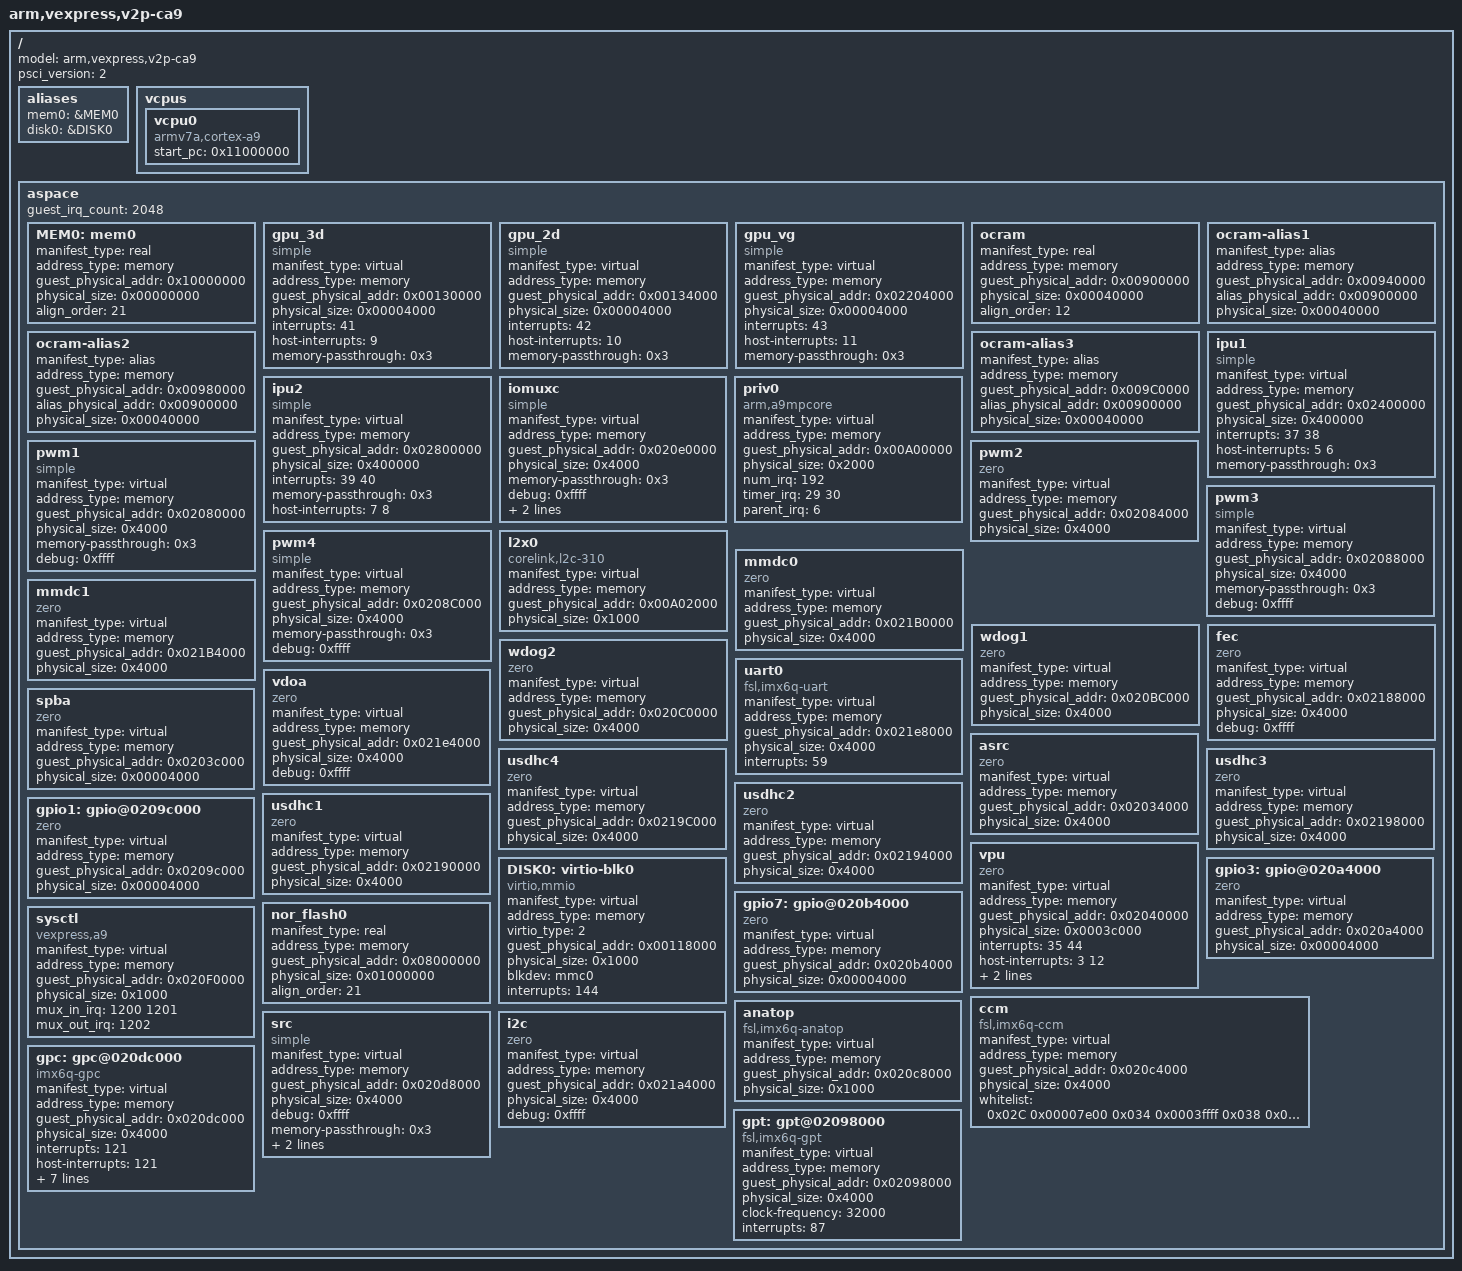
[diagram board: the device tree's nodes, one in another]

/dts-v1/;

/ {
	model = "arm,vexpress,v2p-ca9";
	device_type = "guest";
	psci_version = <2>;

	aliases {
		mem0 = &MEM0;
		//net0 = &NET0;
		disk0 = &DISK0;
	};

	vcpus {
		vcpu0 {
			device_type = "vcpu";
			compatible = "armv7a,cortex-a9";
			start_pc = <0x11000000>;
		};

		/* vcpu1 { */
		/* 	device_type = "vcpu"; */
		/* 	compatible = "armv7a,cortex-a9"; */
		/* 	start_pc = <0xC1000000>; */
		/* }; */
	};

	aspace {
		guest_irq_count = <2048>;

		MEM0: mem0 {
			manifest_type = "real";
			address_type = "memory";
			guest_physical_addr = <0x10000000>;
			physical_size = <0x00000000>; /* Override this before guest creation */
			align_order = <21>; /* Align alloced memory to 2MB */
			device_type = "alloced_ram";
		};

		gpu_3d {
			manifest_type = "virtual";
			address_type = "memory";
			guest_physical_addr = <0x00130000>;
			physical_size = <0x00004000>;
			interrupts = <41>;
			host-interrupts = <9>;
			memory-passthrough = <0x3>;
			//debug = <0xffffffff>;
			device_type = "pt";
			compatible = "simple";
		};

		gpu_2d {
			manifest_type = "virtual";
			address_type = "memory";
			guest_physical_addr = <0x00134000>;
			physical_size = <0x00004000>;
			interrupts = <42>;
			host-interrupts = <10>;
			memory-passthrough = <0x3>;
			device_type = "pt";
			compatible = "simple";
			//debug = <0xffffffff>;
		};

		gpu_vg {
			manifest_type = "virtual";
			address_type = "memory";
			guest_physical_addr = <0x02204000>;
			physical_size = <0x00004000>;
			interrupts = <43>;
			host-interrupts = <11>;
			memory-passthrough = <0x3>;
			//debug = <0xffffffff>;
			device_type = "pt";
			compatible = "simple";
		};

		ocram {
			manifest_type = "real";
			address_type = "memory";
			guest_physical_addr = <0x00900000>;
			physical_size = <0x00040000>;
			align_order = <12>; /* Align alloced memory to 4K */
			device_type = "alloced_ram";
		};

		ocram-alias1 {
			manifest_type = "alias";
			address_type = "memory";
			guest_physical_addr = <0x00940000>;
			alias_physical_addr = <0x00900000>;
			physical_size = <0x00040000>;
			device_type = "ram";
		};

		ocram-alias2 {
			manifest_type = "alias";
			address_type = "memory";
			guest_physical_addr = <0x00980000>;
			alias_physical_addr = <0x00900000>;
			physical_size = <0x00040000>;
			device_type = "ram";
		};

		ocram-alias3 {
			manifest_type = "alias";
			address_type = "memory";
			guest_physical_addr = <0x009C0000>;
			alias_physical_addr = <0x00900000>;
			physical_size = <0x00040000>;
			device_type = "ram";
		};

		ipu1 {
			manifest_type = "virtual";
			address_type = "memory";
			guest_physical_addr = <0x02400000>;
			physical_size = <0x400000>;
			interrupts = <37 38>;
			host-interrupts = <5 6>;
			memory-passthrough = <0x3>;
			device_type = "pt";
			compatible = "simple";
			///debug = <0xffff>;
		};

		ipu2 {
			manifest_type = "virtual";
			address_type = "memory";
			guest_physical_addr = <0x02800000>;
			physical_size = <0x400000>;
			interrupts = <39 40>;
			memory-passthrough = <0x3>;
			host-interrupts = <7 8>;
			device_type = "pt";
			compatible = "simple";
			///debug = <0xffff>;
		};

		iomuxc {
			manifest_type = "virtual";
			address_type = "memory";
			guest_physical_addr = <0x020e0000>;
			physical_size = <0x4000>;
			device_type = "pt";
			compatible = "simple";
			memory-passthrough = <0x3>;
			//device_type = "misc";
			//compatible = "fsl,imx6q-iomuxc";
			debug = <0xffff>;
			whitelist = <
				0x004 0x00021000
				0x008 0xffffffff /* LDB */
				0x00C 0x600007ff
				0x010 0x000000ff
				0x018 0xffffffff
				0x01C 0xffffffff

				0x15C 0xffffffff
				0x160 0xffffffff
				0x164 0xffffffff
				0x168 0xffffffff
				0x170 0xffffffff
				0x174 0xffffffff
				0x178 0xffffffff
				0x17C 0xffffffff
				0x180 0xffffffff
				0x184 0xffffffff
				0x188 0xffffffff
				0x18C 0xffffffff
				0x190 0xffffffff
				0x194 0xffffffff
				0x198 0xffffffff
				0x19C 0xffffffff
				0x1A0 0xffffffff
				0x1A4 0xffffffff
				0x1A8 0xffffffff
				0x1AC 0xffffffff
				0x1B0 0xffffffff
				0x1B4 0xffffffff
				0x1B8 0xffffffff
				0x1BC 0xffffffff
				0x1C0 0xffffffff
				0x1C4 0xffffffff
				0x1C8 0xffffffff
				0x1CC 0xffffffff

				0x470 0xffffffff
				0x474 0xffffffff
				0x478 0xffffffff
				0x47C 0xffffffff
				0x484 0xffffffff
				0x488 0xffffffff
				0x48C 0xffffffff
				0x490 0xffffffff
				0x494 0xffffffff
				0x498 0xffffffff
				0x49C 0xffffffff
				0x4A0 0xffffffff
				0x4A4 0xffffffff
				0x4A8 0xffffffff
				0x4AC 0xffffffff
				0x4B0 0xffffffff
				0x4B4 0xffffffff
				0x4B8 0xffffffff
				0x4BC 0xffffffff
				0x4C0 0xffffffff
				0x4C4 0xffffffff
				0x4C8 0xffffffff
				0x4CC 0xffffffff
				0x4D0 0xffffffff
				0x4D4 0xffffffff
				0x4D8 0xffffffff
				0x4DC 0xffffffff
				0x4E0 0xffffffff
			>;
		//	device_type = "pt";
		//	memory-passthrough = <0x3>;
		//	compatible = "simple";
		//	host-interrupts = <32>;
		//	interrupts = <32>;
		};

		//dma_apbh {
		//	manifest_type = "virtual";
		//	address_type = "memory";
		//	guest_physical_addr = <0x00110000>;
		//	physical_size = <0x2000>;
		//	device_type = "misc";
		//	compatible = "fsl,imx6q-dma-apbh";
		//	debug = <0xffff>;
		//};

		priv0 {
			manifest_type = "virtual";
			address_type = "memory";
			guest_physical_addr = <0x00A00000>;
			physical_size = <0x2000>;
			device_type = "misc";
			compatible = "arm,a9mpcore";
			num_irq = <192>;
			timer_irq = <29 30>;
			parent_irq = <6>;
		//	debug = <0xffff>;
		};

		pwm1 {
			manifest_type = "virtual";
			address_type = "memory";
			guest_physical_addr = <0x02080000>;
			physical_size = <0x4000>;

			//device_type = "misc";
			//compatible = "zero";
			device_type = "pt";
			compatible = "simple";
			memory-passthrough = <0x3>;
			debug = <0xffff>;
		};

		pwm2 {
			manifest_type = "virtual";
			address_type = "memory";
			guest_physical_addr = <0x02084000>;
			physical_size = <0x4000>;
			device_type = "misc";
			compatible = "zero";
		};

		pwm3 {
			manifest_type = "virtual";
			address_type = "memory";
			guest_physical_addr = <0x02088000>;
			physical_size = <0x4000>;
			//device_type = "misc";
			//compatible = "zero";

			device_type = "pt";
			compatible = "simple";
			memory-passthrough = <0x3>;
			debug = <0xffff>;
		};

		pwm4 {
			manifest_type = "virtual";
			address_type = "memory";
			guest_physical_addr = <0x0208C000>;
			physical_size = <0x4000>;

			device_type = "pt";
			compatible = "simple";
			memory-passthrough = <0x3>;
			debug = <0xffff>;
			//device_type = "misc";
			//compatible = "zero";
		};

		l2x0 {
			manifest_type = "virtual";
			address_type = "memory";
			guest_physical_addr = <0x00A02000>;
			physical_size = <0x1000>;
			device_type = "cache";
			compatible = "corelink,l2c-310";
		};

                mmdc0 {
			manifest_type = "virtual";
			address_type = "memory";
			guest_physical_addr = <0x021B0000>;
			physical_size = <0x4000>;
			device_type = "misc";
			compatible = "zero";
                };

                mmdc1 {
			manifest_type = "virtual";
			address_type = "memory";
			guest_physical_addr = <0x021B4000>;
			physical_size = <0x4000>;
			device_type = "misc";
			compatible = "zero";
                };

		wdog1 {
			manifest_type = "virtual";
			address_type = "memory";
			guest_physical_addr = <0x020BC000>;
			physical_size = <0x4000>;
			device_type = "misc";
			compatible = "zero";
		};

                fec {
			manifest_type = "virtual";
			address_type = "memory";
			guest_physical_addr = <0x02188000>;
			physical_size = <0x4000>;
			device_type = "misc";
			debug = <0xffff>;
			compatible = "zero";
                };

		wdog2 {
			manifest_type = "virtual";
			address_type = "memory";
			guest_physical_addr = <0x020C0000>;
			physical_size = <0x4000>;
			device_type = "misc";
			compatible = "zero";
		};

		uart0 {
			manifest_type = "virtual";
			address_type = "memory";
			guest_physical_addr = <0x021e8000>;
			physical_size = <0x4000>;
			device_type = "serial";
			compatible = "fsl,imx6q-uart", "fsl,imx21-uart";
			interrupts = <59>;
		};

		vdoa {
			manifest_type = "virtual";
			address_type = "memory";
			guest_physical_addr = <0x021e4000>;
			physical_size = <0x4000>;
			device_type = "misc";
			compatible = "zero";
			debug = <0xffff>;
		};

		spba {
			manifest_type = "virtual";
			address_type = "memory";
			guest_physical_addr = <0x0203c000>;
			physical_size = <0x00004000>;
			device_type = "misc";
			compatible = "zero";
		};

		//sdma {
		//	manifest_type = "virtual";
		//	address_type = "memory";
		//	guest_physical_addr = <0x020ec000>;
		//	physical_size = <0x4000>;
		//	device_type = "misc";
		//	compatible = "zero";
                //};

                asrc {
			manifest_type = "virtual";
			address_type = "memory";
			guest_physical_addr = <0x02034000>;
			physical_size = <0x4000>;
			device_type = "misc";
			compatible = "zero";
		};

                usdhc4 {
			manifest_type = "virtual";
			address_type = "memory";
			guest_physical_addr = <0x0219C000>;
			physical_size = <0x4000>;
			device_type = "misc";
			compatible = "zero";
                };

                usdhc3 {
			manifest_type = "virtual";
			address_type = "memory";
			guest_physical_addr = <0x02198000>;
			physical_size = <0x4000>;
			device_type = "misc";
			compatible = "zero";
		};

                usdhc2 {
			manifest_type = "virtual";
			address_type = "memory";
			guest_physical_addr = <0x02194000>;
			physical_size = <0x4000>;
			device_type = "misc";
			compatible = "zero";
                };

                usdhc1 {
			manifest_type = "virtual";
			address_type = "memory";
			guest_physical_addr = <0x02190000>;
			physical_size = <0x4000>;
			device_type = "misc";
			compatible = "zero";
                };

		vpu {
			manifest_type = "virtual";
			address_type = "memory";
			guest_physical_addr = <0x02040000>;
			physical_size = <0x0003c000>;
			interrupts = <35 44>;
			host-interrupts = <3 12>;
			memory-passthrough = <0x3>;
			device_type = "misc";
			compatible = "zero";
			debug = <0xffff>;
	//		device_type = "pt";
	//		compatible = "simple";
		};

		DISK0: virtio-blk0 {
			manifest_type = "virtual";
			address_type = "memory";
			device_type = "virtio";
			compatible = "virtio,mmio";
			virtio_type = <2>; /* virtio_blk */
			guest_physical_addr = <0x00118000>; /* In a "reserved" region */
			physical_size = <0x1000>;
			blkdev = "mmc0"; // XXX: this is just the second partition on the sd card
			interrupts = <144>;
		};

		gpio1: gpio@0209c000 {
			manifest_type = "virtual";
			address_type = "memory";
			guest_physical_addr = <0x0209c000>;
			physical_size = <0x00004000>;
			device_type = "misc";
			compatible = "zero";
		};

		gpio3: gpio@020a4000 {
			manifest_type = "virtual";
			address_type = "memory";
			guest_physical_addr = <0x020a4000>;
			physical_size = <0x00004000>;
			device_type = "misc";
			compatible = "zero";
		};

		gpio7: gpio@020b4000 {
			manifest_type = "virtual";
			address_type = "memory";
			guest_physical_addr = <0x020b4000>;
			physical_size = <0x00004000>;
			device_type = "misc";
			compatible = "zero";
		};

		nor_flash0 {
			manifest_type = "real";
			address_type = "memory";
			guest_physical_addr = <0x08000000>;
			physical_size = <0x01000000>;
			device_type = "alloced_rom";
			align_order = <21>; /* Align alloced memory to 2MB */
		};

		/* Use a reserved i.MX6 area to emulate VExpress-A9 sysctl */
		sysctl {
			manifest_type = "virtual";
			address_type = "memory";
			guest_physical_addr = <0x020F0000>;
			physical_size = <0x1000>;
			device_type = "sys";
			compatible = "vexpress,a9";
			mux_in_irq = <1200 1201>;
			mux_out_irq = <1202>;
		};

		ccm {
			manifest_type = "virtual";
			address_type = "memory";
			guest_physical_addr = <0x020c4000>;
			physical_size = <0x4000>;
			device_type = "misc";
			compatible = "fsl,imx6q-ccm";
		//	debug = <0xffff>;
			whitelist = <
				0x02C 0x00007e00
				0x034 0x0003ffff
				0x038 0x0003ffff
				0x074 0x0000ffff
				0x060 0x01ff017f
				0x06C 0x0f000000
				0x080 0x0000c000
				0x020 0x0c000000
				0x018 0xff83c333
				0x03C 0x0007fe00
				0x088 0x00000c00
			>;
		};

		anatop {
			manifest_type = "virtual";
			address_type = "memory";
			guest_physical_addr = <0x020c8000>;
			physical_size = <0x1000>;
			device_type = "misc";
			compatible = "fsl,imx6q-anatop";
		};

		src {
			manifest_type = "virtual";
			address_type = "memory";
			guest_physical_addr = <0x020d8000>;
			physical_size = <0x4000>;
//			device_type = "misc";
//			compatible = "zero";
			//debug = <0xffff>;

			debug = <0xffff>;
			device_type = "pt";
			compatible = "simple";
			memory-passthrough = <0x3>;
			whitelist = <
				0x000 0x0000101e
				0x014 0x0000001f
				0x018 0x0000001f
			>;
		};

		i2c {
			manifest_type = "virtual";
			address_type = "memory";
			guest_physical_addr = <0x021a4000>;
			physical_size = <0x4000>;
			device_type = "misc";
			compatible = "zero";
			debug = <0xffff>;
		};

		gpc: gpc@020dc000 {
			manifest_type = "virtual";
			address_type = "memory";
			guest_physical_addr = <0x020dc000>;
			physical_size = <0x4000>;
			interrupts = <121>;
			host-interrupts = <121>;
			device_type = "pt";
			compatible = "imx6q-gpc";
			//debug = <0xffffffff>;
			/* CNTR Mask:
			 *  - GPCIRQM
			 *  - DVFS0CR
			 *  - gpu_vpu_pup_req
			 *  - gpu_vpu_pdn_req */
			cntr-mask = <0x00210003>;

			imr-masks = <0x00001fe8>, /* VPU, IPUs, GPU2D, GPU3D */
				<0x00000000>,
				<0x00000000>,
				<0x00000000>;

			//pgcr-mask = <0x00000001>; /* Power control */
			pupscr-mask = <0x00003f3f>; /* All non-reserved fields */
			pdnscr-mask = <0x00003f3f>; /* All non-reserved fields */
			pgsr-mask = <0x00000001>; /* Power control status */

			debug = <0xffff>;
		};

		gpt: gpt@02098000 {
			manifest_type = "virtual";
			address_type = "memory";
			guest_physical_addr = <0x02098000>;
			physical_size = <0x4000>;
			device_type = "timer";
			compatible = "fsl,imx6q-gpt";
			clock-frequency = <32000>;
			interrupts = <87>;
			//debug = <0xffff>;
		};
	};
};
